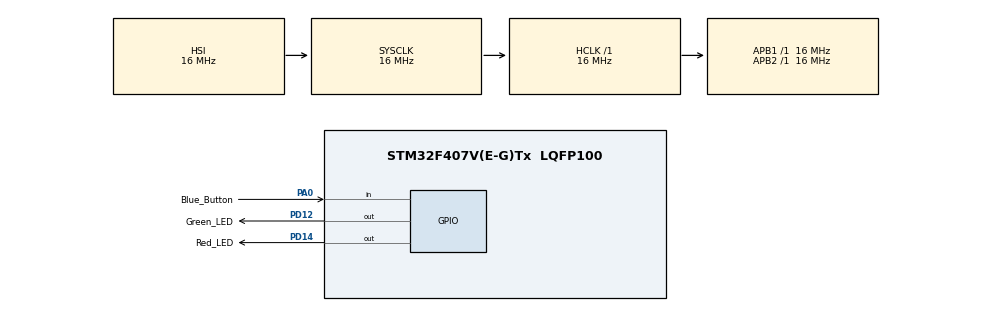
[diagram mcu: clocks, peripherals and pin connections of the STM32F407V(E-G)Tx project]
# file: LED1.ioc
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FREERTOS.Queues01=myQueue01,16,uint16_t,0,Dynamic,NULL,NULL
FREERTOS.Tasks01=LEDTask,0,128,LEDTask_App,Default,NULL,Dynamic,NULL,NULL;LBtnTask,0,128,LBtnTask_App,Default,NULL,Dynamic,NULL,NULL
FREERTOS.configMINIMAL_STACK_SIZE=128
FREERTOS.configTOTAL_HEAP_SIZE=1500
Mcu.Family=STM32F4
Mcu.Name=STM32F407V(E-G)Tx
Mcu.Package=LQFP100
NVIC.PriorityGroup=NVIC_PRIORITYGROUP_4
NVIC.TIM6_DAC_IRQn=true\:0\:0\:false\:false\:true\:false\:false\:true
NVIC.TimeBase=TIM6_DAC_IRQn
NVIC.TimeBaseIP=TIM6
PA0-WKUP.GPIO_Label=Blue_Button
PA0-WKUP.Signal=GPIO_Input
PA13.Mode=Serial_Wire
PA13.Signal=SYS_JTMS-SWDIO
PA14.Mode=Serial_Wire
PA14.Signal=SYS_JTCK-SWCLK
PD12.GPIO_Label=Green_LED
PD12.Signal=GPIO_Output
PD14.GPIO_Label=Red_LED
PD14.Signal=GPIO_Output
PH0-OSC_IN.Mode=HSE-External-Oscillator
PH0-OSC_IN.Signal=RCC_OSC_IN
PH1-OSC_OUT.Mode=HSE-External-Oscillator
PH1-OSC_OUT.Signal=RCC_OSC_OUT
ProjectManager.HeapSize=0x200
ProjectManager.StackSize=0x400
ProjectManager.TargetToolchain=STM32CubeIDE
RCC.AHBFreq_Value=16000000
RCC.APB1Freq_Value=16000000
RCC.APB2Freq_Value=16000000
RCC.CortexFreq_Value=16000000
RCC.HSE_VALUE=25000000
RCC.HSI_VALUE=16000000
RCC.LSE_VALUE=32768
RCC.SYSCLKFreq_VALUE=16000000
RCC.VCOOutputFreq_Value=192000000
VP_FREERTOS_VS_CMSIS_V1.Mode=CMSIS_V1
VP_SYS_VS_tim6.Mode=TIM6
board=custom

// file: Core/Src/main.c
/* USER CODE BEGIN Header */
/**
  ******************************************************************************
  * @file           : main.c
  * @brief          : Main program body
  ******************************************************************************
  * @attention
  *
  * <h2><center>&copy; Copyright (c) 2021 STMicroelectronics.
  * All rights reserved.</center></h2>
  *
  * This software component is licensed by ST under BSD 3-Clause license,
  * the "License"; You may not use this file except in compliance with the
  * License. You may obtain a copy of the License at:
  *                        opensource.org/licenses/BSD-3-Clause
  *
  ******************************************************************************
  */
/* USER CODE END Header */
#include "main.h"
#include "cmsis_os.h"

osThreadId LEDTaskHandle;
osThreadId LBtnTaskHandle;
osMessageQId myQueue01Handle;

void SystemClock_Config(void);
static void MX_GPIO_Init(void);
void LEDTask_App(void const * argument);
void LBtnTask_App(void const * argument);

int main(void)
{

  /* MCU Configuration--------------------------------------------------------*/

  /* Reset of all peripherals, Initializes the Flash interface and the Systick. */
  HAL_Init();

  /* Configure the system clock */
  SystemClock_Config();

  /* Initialize all configured peripherals */
  MX_GPIO_Init();

  /* Create the queue(s) */
  /* definition and creation of myQueue01 */
  osMessageQDef(myQueue01, 16, uint16_t);
  myQueue01Handle = osMessageCreate(osMessageQ(myQueue01), NULL);

  /* Create the thread(s) */
  /* definition and creation of LEDTask */
  osThreadDef(LEDTask, LEDTask_App, osPriorityNormal, 0, 128);
  LEDTaskHandle = osThreadCreate(osThread(LEDTask), NULL);

  /* definition and creation of LBtnTask */
  osThreadDef(LBtnTask, LBtnTask_App, osPriorityNormal, 0, 128);
  LBtnTaskHandle = osThreadCreate(osThread(LBtnTask), NULL);

  /* Start scheduler */
  osKernelStart();

  /* We should never get here as control is now taken by the scheduler */
  /* Infinite loop */
  while (1)
  {

  }
}

void SystemClock_Config(void)
{
  RCC_OscInitTypeDef RCC_OscInitStruct = {0};
  RCC_ClkInitTypeDef RCC_ClkInitStruct = {0};

  /** Configure the main internal regulator output voltage
  */
  __HAL_RCC_PWR_CLK_ENABLE();
  __HAL_PWR_VOLTAGESCALING_CONFIG(PWR_REGULATOR_VOLTAGE_SCALE1);
  /** Initializes the RCC Oscillators according to the specified parameters
  * in the RCC_OscInitTypeDef structure.
  */
  RCC_OscInitStruct.OscillatorType = RCC_OSCILLATORTYPE_HSI;
  RCC_OscInitStruct.HSIState = RCC_HSI_ON;
  RCC_OscInitStruct.HSICalibrationValue = RCC_HSICALIBRATION_DEFAULT;
  RCC_OscInitStruct.PLL.PLLState = RCC_PLL_NONE;
  if (HAL_RCC_OscConfig(&RCC_OscInitStruct) != HAL_OK)
  {
    Error_Handler();
  }
  /** Initializes the CPU, AHB and APB buses clocks
  */
  RCC_ClkInitStruct.ClockType = RCC_CLOCKTYPE_HCLK|RCC_CLOCKTYPE_SYSCLK
                              |RCC_CLOCKTYPE_PCLK1|RCC_CLOCKTYPE_PCLK2;
  RCC_ClkInitStruct.SYSCLKSource = RCC_SYSCLKSOURCE_HSI;
  RCC_ClkInitStruct.AHBCLKDivider = RCC_SYSCLK_DIV1;
  RCC_ClkInitStruct.APB1CLKDivider = RCC_HCLK_DIV1;
  RCC_ClkInitStruct.APB2CLKDivider = RCC_HCLK_DIV1;

  if (HAL_RCC_ClockConfig(&RCC_ClkInitStruct, FLASH_LATENCY_0) != HAL_OK)
  {
    Error_Handler();
  }
}

static void MX_GPIO_Init(void)
{
  GPIO_InitTypeDef GPIO_InitStruct = {0};

  /* GPIO Ports Clock Enable */
  __HAL_RCC_GPIOH_CLK_ENABLE();
  __HAL_RCC_GPIOA_CLK_ENABLE();
  __HAL_RCC_GPIOD_CLK_ENABLE();

  /*Configure GPIO pin Output Level */
  HAL_GPIO_WritePin(GPIOD, Green_LED_Pin|Red_LED_Pin, GPIO_PIN_RESET);

  /*Configure GPIO pin : Blue_Button_Pin */
  GPIO_InitStruct.Pin = Blue_Button_Pin;
  GPIO_InitStruct.Mode = GPIO_MODE_INPUT;
  GPIO_InitStruct.Pull = GPIO_NOPULL;
  HAL_GPIO_Init(Blue_Button_GPIO_Port, &GPIO_InitStruct);

  /*Configure GPIO pins : Green_LED_Pin Red_LED_Pin */
  GPIO_InitStruct.Pin = Green_LED_Pin|Red_LED_Pin;
  GPIO_InitStruct.Mode = GPIO_MODE_OUTPUT_PP;
  GPIO_InitStruct.Pull = GPIO_NOPULL;
  GPIO_InitStruct.Speed = GPIO_SPEED_FREQ_LOW;
  HAL_GPIO_Init(GPIOD, &GPIO_InitStruct);

}

void LEDTask_App(void const * argument)
{
  /* USER CODE BEGIN 5 */
  /* Infinite loop */
  osEvent osevent;
  int Busy_waiting_count;
  int Change_state_flag = 0; // It's for change state with "busy waiting".
  int BRW;  // It's for break while with "busy waiting" .

  for(;;){
	  Busy_waiting_count = 0;
	  BRW = 1;
	  if(Change_state_flag){
		  while(BRW){
			  HAL_GPIO_WritePin(Green_LED_GPIO_Port,GPIO_PIN_12,GPIO_PIN_RESET); //Close the green LED
			  Busy_waiting_count = 0;
			  HAL_GPIO_WritePin(Red_LED_GPIO_Port,GPIO_PIN_14,GPIO_PIN_SET);
			  while((Busy_waiting_count < 20000)){
				  Busy_waiting_count++;
				  osevent= osMessageGet( myQueue01Handle,0);
				  if(osevent.status==osEventMessage){ // When a message is received from the queue
					  BRW = 0; // break while
					  Change_state_flag = 0; // Set change status flag
					  break;
				  }
			  }
			  HAL_GPIO_WritePin(Red_LED_GPIO_Port,GPIO_PIN_14,GPIO_PIN_RESET);
			  Busy_waiting_count = 0;
			  while((Busy_waiting_count < 20000) &  BRW){
				  Busy_waiting_count++;
				  osevent= osMessageGet( myQueue01Handle,0);
				  if(osevent.status==osEventMessage){
					  BRW = 0;
					  Change_state_flag = 0;
					  break;
				  }
			  }
		  }
	  }else{
		  while(BRW){
			  HAL_GPIO_WritePin(Red_LED_GPIO_Port,GPIO_PIN_14,GPIO_PIN_RESET);
			  Busy_waiting_count = 0;
			  HAL_GPIO_WritePin(Green_LED_GPIO_Port,GPIO_PIN_12,GPIO_PIN_SET);
			  while((Busy_waiting_count < 120000)){
				  Busy_waiting_count++;
				  osevent= osMessageGet( myQueue01Handle,0);
				  if(osevent.status==osEventMessage){
					  BRW = 0;
					  Change_state_flag = 1;
					  break;
				  }
			  }
			  HAL_GPIO_WritePin(Green_LED_GPIO_Port,GPIO_PIN_12,GPIO_PIN_RESET);
			  HAL_GPIO_WritePin(Red_LED_GPIO_Port,GPIO_PIN_14,GPIO_PIN_SET);
			  Busy_waiting_count = 0;
			  while((Busy_waiting_count < 120000) &  BRW){
				  Busy_waiting_count++;
				  osevent= osMessageGet( myQueue01Handle,0);
				  if(osevent.status==osEventMessage){
					  BRW = 0;
					  Change_state_flag = 1;
					  break;
				  }
			  }
		  }
	  }
  }
  /* USER CODE END 5 */
}

void LBtnTask_App(void const * argument)
{
  /* USER CODE BEGIN LBtnTask_App */
  /* Infinite loop */
  uint8_t curr_state,prev_state = 0; //State for the button，Used to solve edge detection.
  uint8_t timer = 0;
  for(;;)
  {
	  timer = 0;
	  while(timer <1){
		  timer ++;
	  }
	  curr_state = HAL_GPIO_ReadPin(Blue_Button_GPIO_Port,GPIO_PIN_0);
	  if((curr_state == 1) && (prev_state == 0)){
		  osMessagePut(myQueue01Handle,1, osWaitForever);
	 }
	  prev_state = curr_state;
  }
  /* USER CODE END LBtnTask_App */
}

 /**
  * @brief  Period elapsed callback in non blocking mode
  * @note   This function is called  when TIM6 interrupt took place, inside
  * HAL_TIM_IRQHandler(). It makes a direct call to HAL_IncTick() to increment
  * a global variable "uwTick" used as application time base.
  * @param  htim : TIM handle
  * @retval None
  */
void HAL_TIM_PeriodElapsedCallback(TIM_HandleTypeDef *htim)
{
  if (htim->Instance == TIM6) {
    HAL_IncTick();
  }
}

void Error_Handler(void)
{
  __disable_irq();
  while (1)
  {
  }
}

/************************ (C) COPYRIGHT STMicroelectronics *****END OF FILE****/
